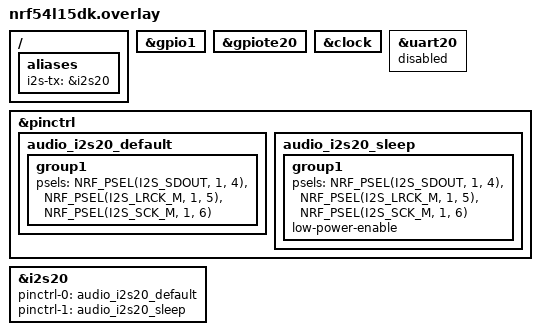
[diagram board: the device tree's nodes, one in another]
#include <zephyr/dt-bindings/pinctrl/nrf-pinctrl.h>

/ {
    aliases {
        i2s-tx = &i2s20;
    };
};

&gpio1 { status = "okay"; };
&gpiote20 { status = "okay"; };
&clock { status = "okay"; };

&uart20 { status = "disabled"; };

&pinctrl {
    audio_i2s20_default: audio_i2s20_default {
        group1 {
            psels = <NRF_PSEL(I2S_SDOUT, 1, 4)>,
                    <NRF_PSEL(I2S_LRCK_M, 1, 5)>,
                    <NRF_PSEL(I2S_SCK_M, 1, 6)>;
        };
    };

    audio_i2s20_sleep: audio_i2s20_sleep {
        group1 {
            psels = <NRF_PSEL(I2S_SDOUT, 1, 4)>,
                    <NRF_PSEL(I2S_LRCK_M, 1, 5)>,
                    <NRF_PSEL(I2S_SCK_M, 1, 6)>;
            low-power-enable;
        };
    };
};

&i2s20 {
    status = "okay";
    pinctrl-0 = <&audio_i2s20_default>;
    pinctrl-1 = <&audio_i2s20_sleep>;
    pinctrl-names = "default", "sleep";
};
